# AT91SAM9G20 register map
Vendor: Atmel; File version: 20130207
CPU: 
Registers are 32-bit, read-write, reset 0x0 unless marked. A register's access mark holds for its fields unless they carry their own. Offsets are from the block's base; [hi:lo] are bit positions; {n}, {i} and the like mark numbered series.

## MATRIX — AHB Bus Matrix
Base 0xFFFFEE00
{0x0+4i} MATRIX_MCFG[{i}] reset not defined (i=0..5) — Master Configuration Register
  [2:0] ULBT — Undefined Length Burst Type
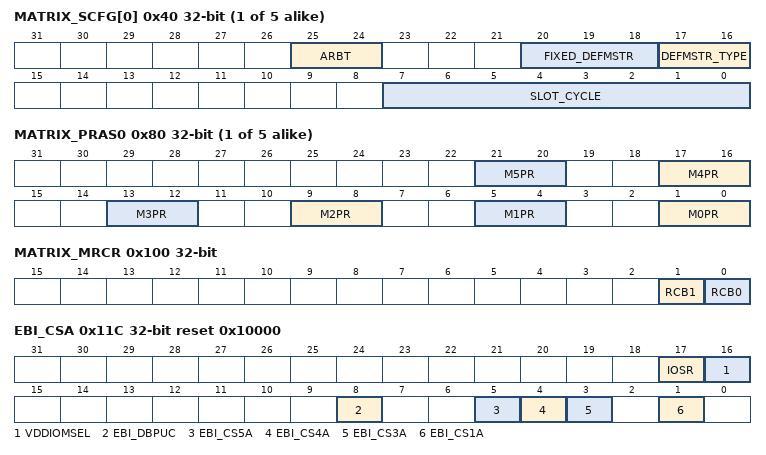
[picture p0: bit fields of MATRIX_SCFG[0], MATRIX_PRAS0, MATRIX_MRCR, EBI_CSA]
{0x40+4i} MATRIX_SCFG[{i}] reset not defined (i=0..4) — Slave Configuration Register
  [25:24] ARBT — Arbitration Type
  [20:18] FIXED_DEFMSTR — Fixed Default Master
  [17:16] DEFMSTR_TYPE — Default Master Type
  [7:0] SLOT_CYCLE — Maximum Number of Allowed Cycles for a Burst
{0x80+8i} MATRIX_PRAS{i} (i=0..4) — Priority Register A for Slave {i}
  [4n+1:4n] M{n}PR (n=0..5) — Master {n} Priority
0x100 MATRIX_MRCR — Master Remap Control Register
  [1] RCB1 — Remap Command Bit for AHB Master 1
  [0] RCB0 — Remap Command Bit for AHB Master 0
0x11C EBI_CSA reset 0x10000 — EBI Chip Select Assignment Register
  [17] IOSR — I/O Slew Rate Selection
  [16] VDDIOMSEL — Memory voltage selection
  [8] EBI_DBPUC — EBI Data Bus Pull-Up Configuration
  [5] EBI_CS5A — EBI Chip Select 5 Assignment
  [4] EBI_CS4A — EBI Chip Select 4 Assignment
  [3] EBI_CS3A — EBI Chip Select 3 Assignment
  [1] EBI_CS1A — EBI Chip Select 1 Assignment

## AIC — Advanced Interrupt Controller
Base 0xFFFFF000; register names take the prefix AIC_
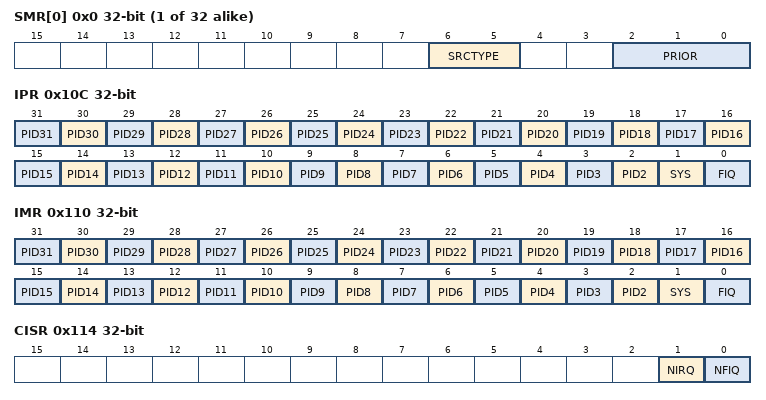
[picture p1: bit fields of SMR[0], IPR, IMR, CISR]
{0x0+4i} SMR[{i}] reset not defined (i=0..31) — Source Mode Register
  [6:5] SRCTYPE — Interrupt Source Type
    0=INT_LEVEL_SENSITIVE (High level Sensitive for internal sourceLow level Sensitive for external source); 1=INT_EDGE_TRIGGERED (Positive edge triggered for internal sourceNegative edge triggered for external source); 2=EXT_HIGH_LEVEL (High level Sensitive for internal sourceHigh level Sensitive for external source); 3=EXT_POSITIVE_EDGE (Positive edge triggered for internal sourcePositive edge triggered for external source)
  [2:0] PRIOR — Priority Level
{0x80+4i} SVR[{i}] reset not defined (i=0..31) — Source Vector Register
  [31:0] VECTOR — Source Vector
0x100 IVR ro — Interrupt Vector Register
  [31:0] IRQV
0x104 FVR ro — FIQ Interrupt Vector Register
  [31:0] FIQV — FIQ Vector Register
0x108 ISR ro — Interrupt Status Register
  [4:0] IRQID — Current Interrupt Identifier
0x10C IPR ro — Interrupt Pending Register
  [n] PID{n} (n=2..31) — Interrupt Pending
  [1] SYS — Interrupt Pending
  [0] FIQ — Interrupt Pending
0x110 IMR ro — Interrupt Mask Register
  [n] PID{n} (n=2..31) — Interrupt Mask
  [1] SYS — Interrupt Mask
  [0] FIQ — Interrupt Mask
0x114 CISR ro — Core Interrupt Status Register
  [1] NIRQ — NIRQ Status
  [0] NFIQ — NFIQ Status
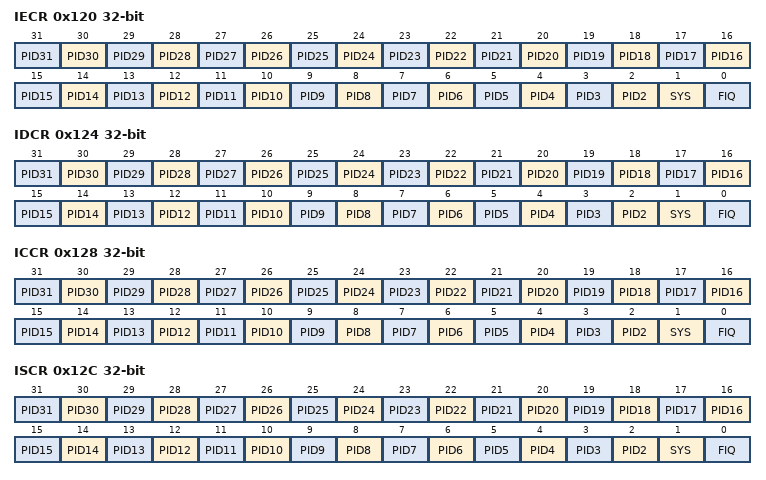
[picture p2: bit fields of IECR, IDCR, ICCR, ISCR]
0x120 IECR wo reset not defined — Interrupt Enable Command Register
  [n] PID{n} (n=2..31) — Interrupt Enable
  [1] SYS — Interrupt Enable
  [0] FIQ — Interrupt Enable
0x124 IDCR wo reset not defined — Interrupt Disable Command Register
  [n] PID{n} (n=2..31) — Interrupt Disable
  [1] SYS — Interrupt Disable
  [0] FIQ — Interrupt Disable
0x128 ICCR wo reset not defined — Interrupt Clear Command Register
  [n] PID{n} (n=2..31) — Interrupt Clear
  [1] SYS — Interrupt Clear
  [0] FIQ — Interrupt Clear
0x12C ISCR wo reset not defined — Interrupt Set Command Register
  [n] PID{n} (n=2..31) — Interrupt Set
  [1] SYS — Interrupt Set
  [0] FIQ — Interrupt Set
0x130 EOICR wo reset not defined — End of Interrupt Command Register
0x134 SPU — Spurious Interrupt Vector Register
  [31:0] SIVR
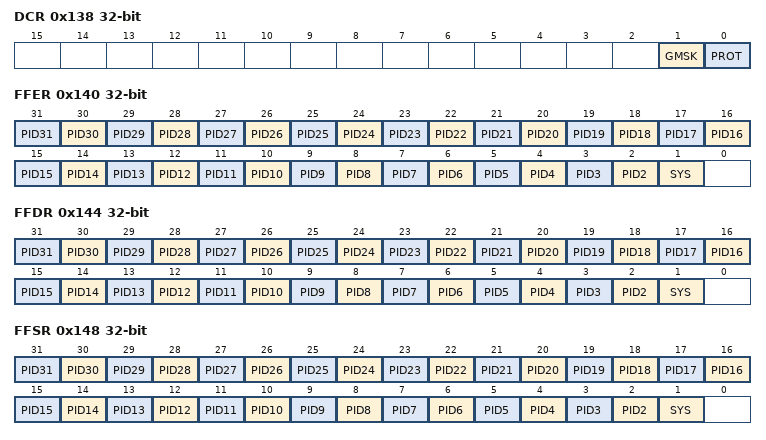
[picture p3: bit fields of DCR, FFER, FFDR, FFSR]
0x138 DCR — Debug Control Register
  [1] GMSK — General Mask
  [0] PROT — Protection Mode
0x140 FFER wo reset not defined — Fast Forcing Enable Register
  [n] PID{n} (n=2..31) — Fast Forcing Enable
  [1] SYS — Fast Forcing Enable
0x144 FFDR wo reset not defined — Fast Forcing Disable Register
  [n] PID{n} (n=2..31) — Fast Forcing Disable
  [1] SYS — Fast Forcing Disable
0x148 FFSR ro — Fast Forcing Status Register
  [n] PID{n} (n=2..31) — Fast Forcing Status
  [1] SYS — Fast Forcing Status
